# CW32F030 register map
Vendor: Wuhan Xinyuan Semiconductor Co.Ltd; Series: ARMCM0P; File version: 1.2
CPU: CM0+ r0p1, little endian, no MPU, no FPU, 3 interrupt priority bits
Registers are 32-bit, read-write, no defined reset value unless marked. A register's access mark holds for its fields unless they carry their own. Offsets are from the block's base; [hi:lo] are bit positions; {n}, {i} and the like mark numbered series.

## GPIOC
Base 0x48000800
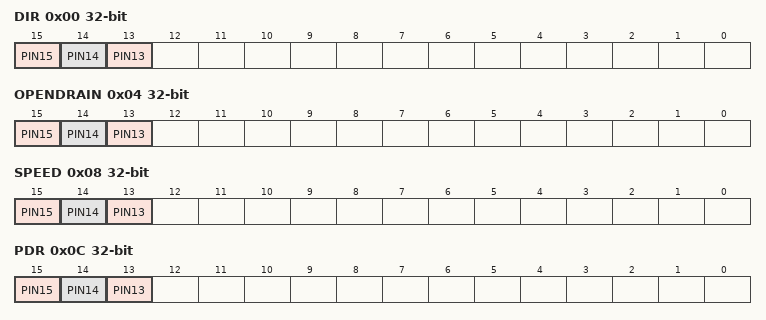
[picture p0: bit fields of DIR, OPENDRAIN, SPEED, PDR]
0x00 DIR
  [15] PIN15, [14] PIN14, [13] PIN13
0x04 OPENDRAIN
  [15] PIN15, [14] PIN14, [13] PIN13
0x08 SPEED
  [15] PIN15, [14] PIN14, [13] PIN13
0x0C PDR
  [15] PIN15, [14] PIN14, [13] PIN13
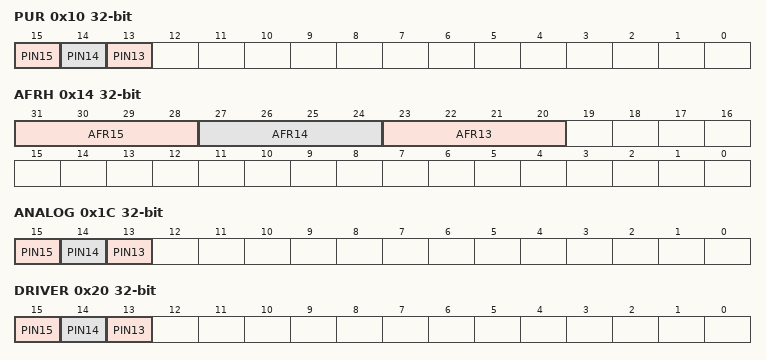
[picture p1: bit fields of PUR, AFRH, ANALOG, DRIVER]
0x10 PUR
  [15] PIN15, [14] PIN14, [13] PIN13
0x14 AFRH
  [31:28] AFR15, [27:24] AFR14, [23:20] AFR13
0x1C ANALOG
  [15] PIN15, [14] PIN14, [13] PIN13
0x20 DRIVER
  [15] PIN15, [14] PIN14, [13] PIN13
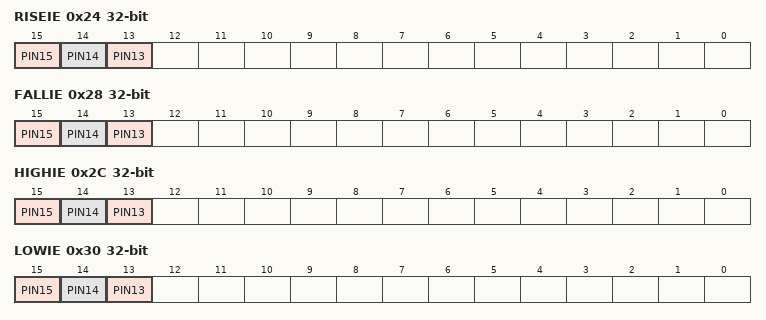
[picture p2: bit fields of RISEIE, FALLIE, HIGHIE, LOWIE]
0x24 RISEIE — Interrupt enable register
  [15] PIN15, [14] PIN14, [13] PIN13
0x28 FALLIE — Interrupt enable register
  [15] PIN15, [14] PIN14, [13] PIN13
0x2C HIGHIE — Interrupt enable register
  [15] PIN15, [14] PIN14, [13] PIN13
0x30 LOWIE — Interrupt enable register
  [15] PIN15, [14] PIN14, [13] PIN13
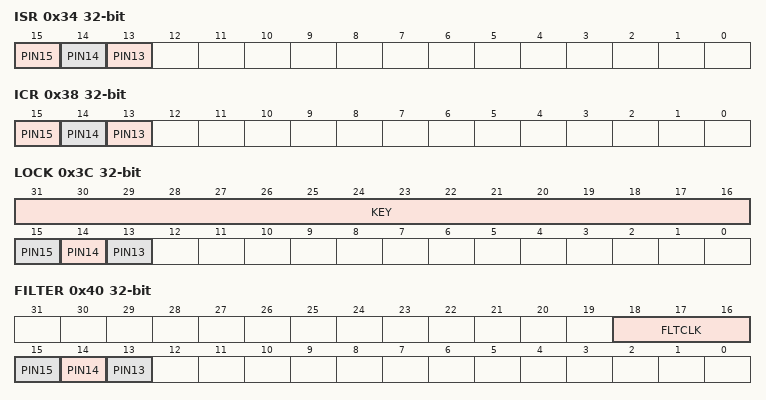
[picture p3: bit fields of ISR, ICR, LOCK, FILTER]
0x34 ISR — Interrupt status register
  [15] PIN15, [14] PIN14, [13] PIN13
0x38 ICR — Interrupt flag clear register
  [15] PIN15, [14] PIN14, [13] PIN13
0x3C LOCK
  [31:16] KEY wo — KEY = 0x5A5A
  [15] PIN15
  [14] PIN14
  [13] PIN13
0x40 FILTER
  [18:16] FLTCLK, [15] PIN15, [14] PIN14, [13] PIN13
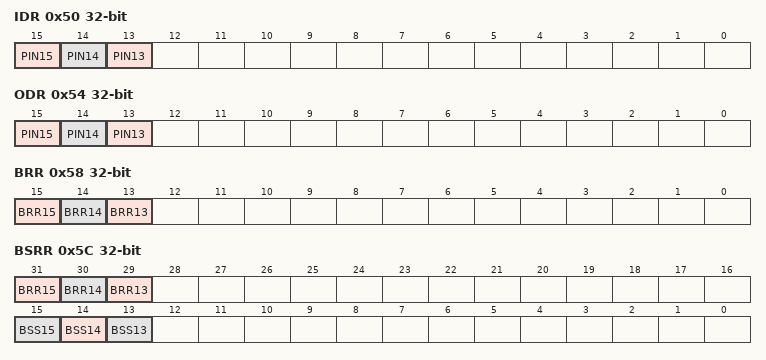
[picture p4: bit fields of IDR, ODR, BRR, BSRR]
0x50 IDR
  [15] PIN15, [14] PIN14, [13] PIN13
0x54 ODR
  [15] PIN15, [14] PIN14, [13] PIN13
0x54 ODRLOWBYTE 8-bit (alternate view of ODR)
  [7:0] LOWBYTE
0x55 ODRHIGHBYTE 8-bit (alternate view of ODR)
  [7:0] HIGHBYTE
0x58 BRR
  [15] BRR15, [14] BRR14, [13] BRR13
0x5C BSRR
  [31] BRR15, [30] BRR14, [29] BRR13, [15] BSS15, [14] BSS14, [13] BSS13
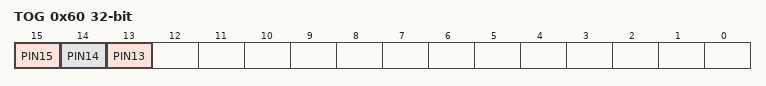
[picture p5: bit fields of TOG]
0x60 TOG
  [15] PIN15, [14] PIN14, [13] PIN13

## GPIOF
Base 0x48001400
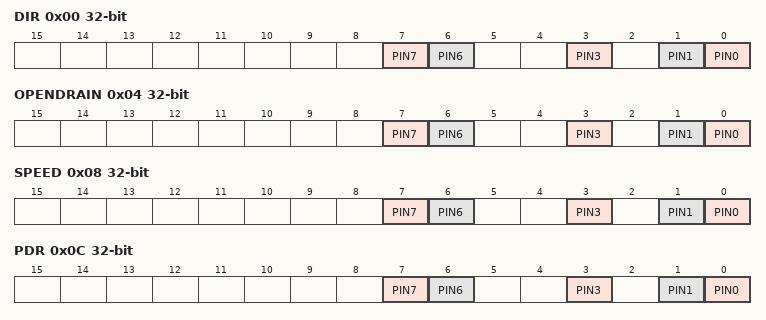
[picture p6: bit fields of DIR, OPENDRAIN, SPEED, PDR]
0x00 DIR
  [7] PIN7, [6] PIN6, [3] PIN3, [1] PIN1, [0] PIN0
0x04 OPENDRAIN
  [7] PIN7, [6] PIN6, [3] PIN3, [1] PIN1, [0] PIN0
0x08 SPEED
  [7] PIN7, [6] PIN6, [3] PIN3, [1] PIN1, [0] PIN0
0x0C PDR
  [7] PIN7, [6] PIN6, [3] PIN3, [1] PIN1, [0] PIN0
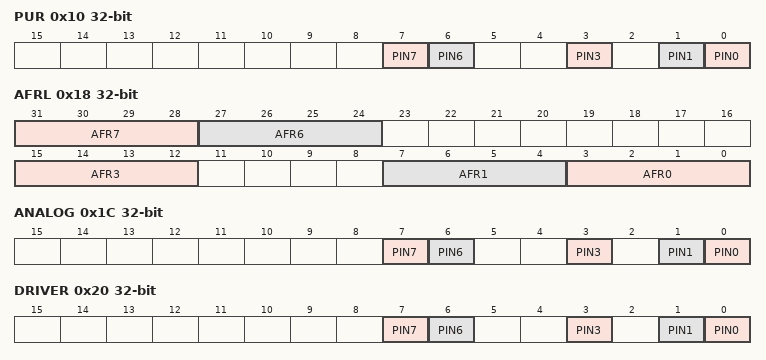
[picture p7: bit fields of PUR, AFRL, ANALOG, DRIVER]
0x10 PUR
  [7] PIN7, [6] PIN6, [3] PIN3, [1] PIN1, [0] PIN0
0x18 AFRL
  [31:28] AFR7, [27:24] AFR6, [15:12] AFR3, [7:4] AFR1, [3:0] AFR0
0x1C ANALOG
  [7] PIN7, [6] PIN6, [3] PIN3, [1] PIN1, [0] PIN0
0x20 DRIVER
  [7] PIN7, [6] PIN6, [3] PIN3, [1] PIN1, [0] PIN0
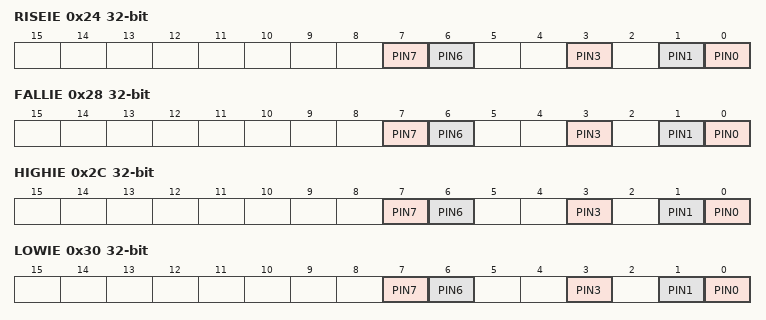
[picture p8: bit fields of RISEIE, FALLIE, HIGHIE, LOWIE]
0x24 RISEIE — Interrupt enable register
  [7] PIN7, [6] PIN6, [3] PIN3, [1] PIN1, [0] PIN0
0x28 FALLIE — Interrupt enable register
  [7] PIN7, [6] PIN6, [3] PIN3, [1] PIN1, [0] PIN0
0x2C HIGHIE — Interrupt enable register
  [7] PIN7, [6] PIN6, [3] PIN3, [1] PIN1, [0] PIN0
0x30 LOWIE — Interrupt enable register
  [7] PIN7, [6] PIN6, [3] PIN3, [1] PIN1, [0] PIN0
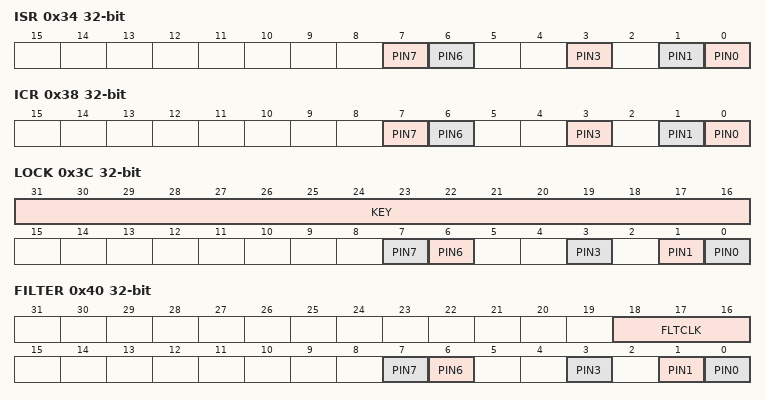
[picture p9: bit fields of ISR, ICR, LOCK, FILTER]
0x34 ISR — Interrupt status register
  [7] PIN7, [6] PIN6, [3] PIN3, [1] PIN1, [0] PIN0
0x38 ICR — Interrupt flag clear register
  [7] PIN7, [6] PIN6, [3] PIN3, [1] PIN1, [0] PIN0
0x3C LOCK
  [31:16] KEY wo — KEY = 0x5A5A
  [7] PIN7
  [6] PIN6
  [3] PIN3
  [1] PIN1
  [0] PIN0
0x40 FILTER
  [18:16] FLTCLK, [7] PIN7, [6] PIN6, [3] PIN3, [1] PIN1, [0] PIN0
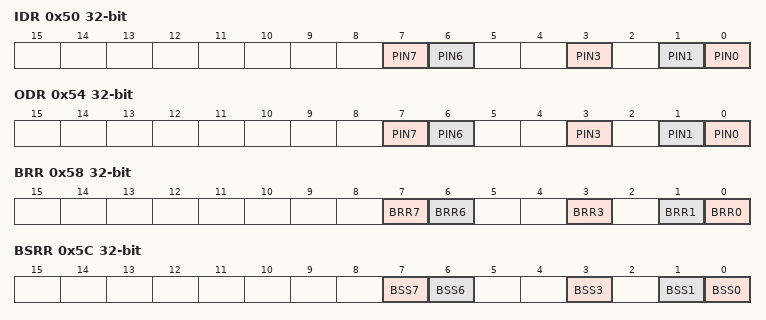
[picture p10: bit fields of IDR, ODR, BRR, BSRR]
0x50 IDR
  [7] PIN7, [6] PIN6, [3] PIN3, [1] PIN1, [0] PIN0
0x54 ODR
  [7] PIN7, [6] PIN6, [3] PIN3, [1] PIN1, [0] PIN0
0x54 ODRLOWBYTE 8-bit (alternate view of ODR)
  [7:0] LOWBYTE
0x58 BRR
  [7] BRR7, [6] BRR6, [3] BRR3, [1] BRR1, [0] BRR0
0x5C BSRR
  [7] BSS7, [6] BSS6, [3] BSS3, [1] BSS1, [0] BSS0
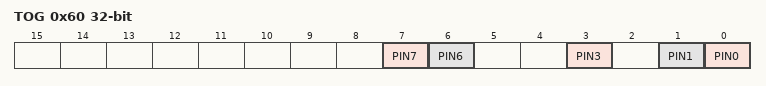
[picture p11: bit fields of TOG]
0x60 TOG
  [7] PIN7, [6] PIN6, [3] PIN3, [1] PIN1, [0] PIN0

## GTIM1 — General Timer 1
Base 0x40000400
Same registers: GTIM2 0x40001000, GTIM3 0x40014000, GTIM4 0x40014400
0x300 ARR — Auto Reload Register
  [15:0] ARR
0x304 CNT — Counter Register
  [15:0] CNT
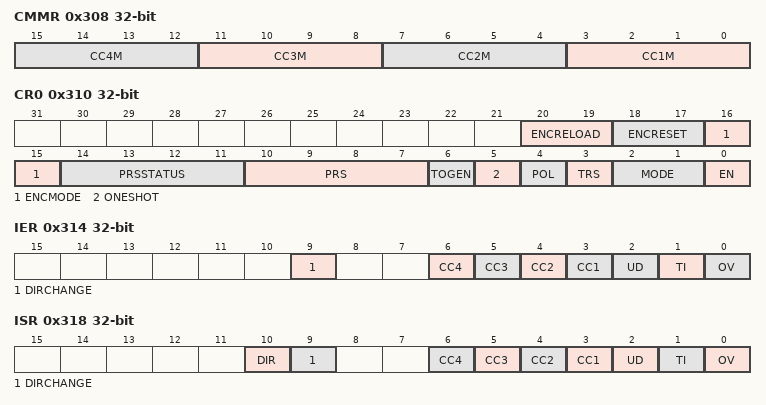
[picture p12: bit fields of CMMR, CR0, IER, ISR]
0x308 CMMR — Capture compare control Register
  [4n-1:4n-4] CC{n}M (n=1..4)
0x30C ETR — ETR Control register
  [6:4] ETRFLT
0x310 CR0 — Control register0
  [20:19] ENCRELOAD, [18:17] ENCRESET, [16:15] ENCMODE, [14:11] PRSSTATUS ro, [10:7] PRS, [6] TOGEN, [5] ONESHOT, [4] POL, [3] TRS, [2:1] MODE, [0] EN
0x314 IER — Interrupt enable register
  [9] DIRCHANGE, [n+2] CC{n} (n=1..4), [2] UD, [1] TI, [0] OV
0x318 ISR — Interrupt status register
  [10] DIR ro, [9] DIRCHANGE ro, [n+2] CC{n} ro (n=1..4), [2] UD ro, [1] TI ro, [0] OV ro
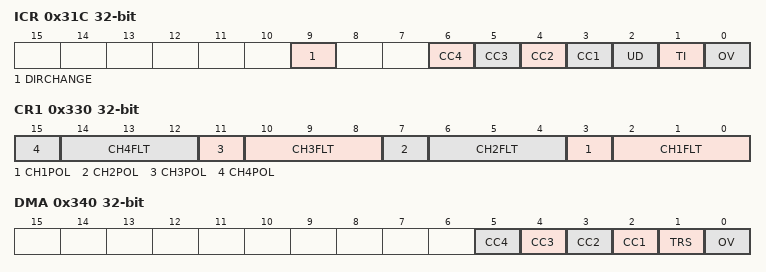
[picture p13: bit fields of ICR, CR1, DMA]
0x31C ICR — Interrupt flag clear register
  [9] DIRCHANGE, [n+2] CC{n} (n=1..4), [2] UD, [1] TI, [0] OV
{0x31C+4i} CCR{i} (i=1..4) — capture compare register
  [15:0] CCR
0x330 CR1 — Control register1
  [4n-1] CH{n}POL (n=1..4), [4n-2:4n-4] CH{n}FLT (n=1..4)
0x340 DMA — DMA Control register
  [n+1] CC{n} (n=1..4), [1] TRS, [0] OV
